# LM4F232E5QC register map
File version: 7944
Registers are 32-bit, read-write, no defined reset value unless marked. A register's access mark holds for its fields unless they carry their own. Offsets are from the block's base; [hi:lo] are bit positions; {n}, {i} and the like mark numbered series.

## EEPROM — Register map for EEPROM peripheral
Base 0x400AF000; register names take the prefix EEPROM
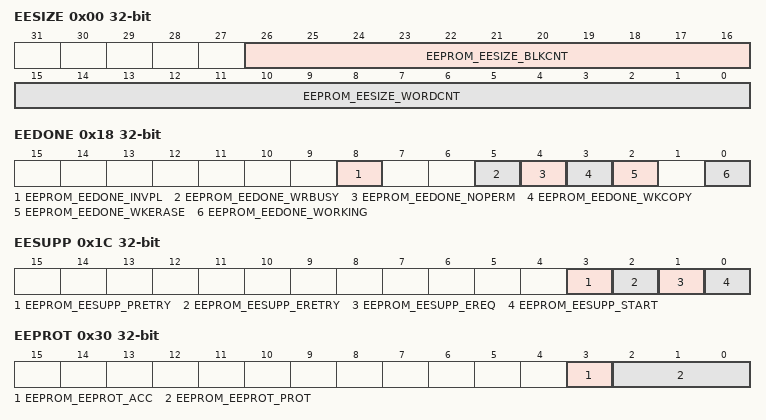
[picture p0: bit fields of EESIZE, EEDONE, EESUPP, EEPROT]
0x00 EESIZE — EEPROM Size Information
  [26:16] EEPROM_EESIZE_BLKCNT — Number of 16-Word Blocks
  [15:0] EEPROM_EESIZE_WORDCNT — Number of 32-Bit Words
0x04 EEBLOCK — EEPROM Current Block
  [15:0] EEPROM_EEBLOCK_BLOCK — Current Block
0x08 EEOFFSET — EEPROM Current Offset
  [3:0] EEPROM_EEOFFSET_OFFSET — Current Address Offset
0x10 EERDWR — EEPROM Read-Write
  [31:0] EEPROM_EERDWR_VALUE — EEPROM Read or Write Data
0x14 EERDWRINC — EEPROM Read-Write with Increment
  [31:0] EEPROM_EERDWRINC_VALUE — EEPROM Read or Write Data with Increment
0x18 EEDONE — EEPROM Done Status
  [8] EEPROM_EEDONE_INVPL — Invalid Program Voltage Level
  [5] EEPROM_EEDONE_WRBUSY — Write Busy
  [4] EEPROM_EEDONE_NOPERM — Write Without Permission
  [3] EEPROM_EEDONE_WKCOPY — Working on a Copy
  [2] EEPROM_EEDONE_WKERASE — Working on an Erase
  [0] EEPROM_EEDONE_WORKING — EEPROM Working
0x1C EESUPP — EEPROM Support Control and Status
  [3] EEPROM_EESUPP_PRETRY — Programming Must Be Retried
  [2] EEPROM_EESUPP_ERETRY — Erase Must Be Retried
  [1] EEPROM_EESUPP_EREQ — Erase Required
  [0] EEPROM_EESUPP_START — Start Erase
0x20 EEUNLOCK — EEPROM Unlock
  [31:0] EEPROM_EEUNLOCK_UNLOCK
0x30 EEPROT — EEPROM Protection
  [3] EEPROM_EEPROT_ACC — Access Control
  [2:0] EEPROM_EEPROT_PROT — Protection Control
    0=EEPROM_EEPROT_PROT_RWNPW (This setting is the default. If there is no password, the block is not protected and is readable and writable); 1=EEPROM_EEPROT_PROT_RWPW (If there is a password, the block is readable or writable only when unlocked); 2=EEPROM_EEPROT_PROT_RONPW (If there is no password, the block is readable, not writable)
{0x34+4i} EEPASS{i} (i=0..2) — EEPROM Password
  [31:0] EEPROM_EEPASS{i}_PASS — Password
0x40 EEINT — EEPROM Interrupt
  [0] EEPROM_EEINT_INT — Interrupt Enable
0x50 EEHIDE — EEPROM Block Hide
  [31:1] EEPROM_EEHIDE_HN — Hide Block
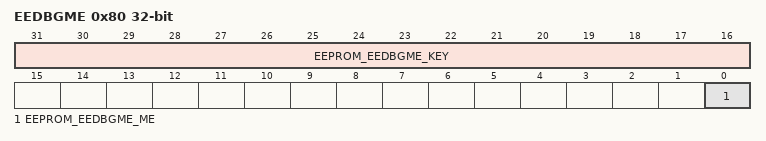
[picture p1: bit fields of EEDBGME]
0x80 EEDBGME — EEPROM Debug Mass Erase
  [31:16] EEPROM_EEDBGME_KEY — Erase Key
  [0] EEPROM_EEDBGME_ME — Mass Erase
0xFC0 EEPROMPP — EEPROM
  [4:0] EEPROM_EEPROMPP_SIZE — EEPROM Size

## SYSEXC — Register map for SYSEXC peripheral
Base 0x400F9000; register names take the prefix SYSEXC
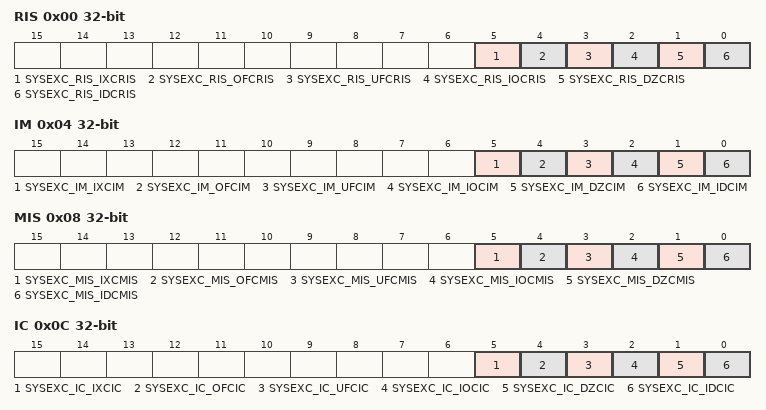
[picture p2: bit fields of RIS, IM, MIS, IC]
0x00 RIS — System Exception Raw Interrupt Status
  [5] SYSEXC_RIS_IXCRIS — Inexact Exception Flag
  [4] SYSEXC_RIS_OFCRIS — Overflow Exception Flag
  [3] SYSEXC_RIS_UFCRIS — Underflow Exception Flag
  [2] SYSEXC_RIS_IOCRIS — Invalid Operation Flag
  [1] SYSEXC_RIS_DZCRIS — Divide By 0 Exception Flag
  [0] SYSEXC_RIS_IDCRIS — Input Denormal Exception Flag
0x04 IM — System Exception Interrupt Mask
  [5] SYSEXC_IM_IXCIM — Inexact Exception Flag
  [4] SYSEXC_IM_OFCIM — Overflow Exception Flag
  [3] SYSEXC_IM_UFCIM — Underflow Exception Flag
  [2] SYSEXC_IM_IOCIM — Invalid Operation Flag
  [1] SYSEXC_IM_DZCIM — Divide By 0 Exception Flag
  [0] SYSEXC_IM_IDCIM — Input Denormal Exception Flag
0x08 MIS — System Exception Raw Interrupt Status
  [5] SYSEXC_MIS_IXCMIS — Inexact Exception Flag
  [4] SYSEXC_MIS_OFCMIS — Overflow Exception Flag
  [3] SYSEXC_MIS_UFCMIS — Underflow Exception Flag
  [2] SYSEXC_MIS_IOCMIS — Invalid Operation Flag
  [1] SYSEXC_MIS_DZCMIS — Divide By 0 Exception Flag
  [0] SYSEXC_MIS_IDCMIS — Input Denormal Exception Flag
0x0C IC wo — System Exception Interrupt Clear
  [5] SYSEXC_IC_IXCIC — Inexact Exception Flag
  [4] SYSEXC_IC_OFCIC — Overflow Exception Flag
  [3] SYSEXC_IC_UFCIC — Underflow Exception Flag
  [2] SYSEXC_IC_IOCIC — Invalid Operation Flag
  [1] SYSEXC_IC_DZCIC — Divide By 0 Exception Flag
  [0] SYSEXC_IC_IDCIC — Input Denormal Exception Flag

## HIB — Register map for HIB peripheral
Base 0x400FC000; register names take the prefix HIB
0x00 RTCC — Hibernation RTC Counter
  [31:0] HIB_RTCC — RTC Counter
0x04 RTCM0 — Hibernation RTC Match 0
  [31:0] HIB_RTCM0 — RTC Match 0
0x0C RTCLD — Hibernation RTC Load
  [31:0] HIB_RTCLD — RTC Load
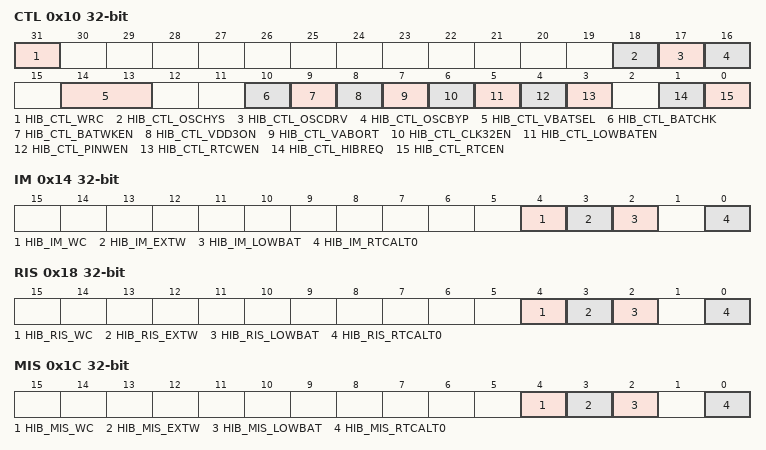
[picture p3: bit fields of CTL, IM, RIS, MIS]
0x10 CTL — Hibernation Control
  [31] HIB_CTL_WRC — Write Complete/Capable
  [18] HIB_CTL_OSCHYS — 32
  [17] HIB_CTL_OSCDRV — Oscillator Drive Capability
  [16] HIB_CTL_OSCBYP — Oscillator Bypass
  [14:13] HIB_CTL_VBATSEL — Select for Low-Battery Comparator
    0=HIB_CTL_VBATSEL_1_9V (1.9 Volts); 1=HIB_CTL_VBATSEL_2_1V (2.1 Volts (default)); 2=HIB_CTL_VBATSEL_2_3V (2.3 Volts); 3=HIB_CTL_VBATSEL_2_5V (2.5 Volts)
  [10] HIB_CTL_BATCHK — Check Battery Status
  [9] HIB_CTL_BATWKEN — Wake on Low Battery
  [8] HIB_CTL_VDD3ON — VDD Powered
  [7] HIB_CTL_VABORT — Power Cut Abort Enable
  [6] HIB_CTL_CLK32EN — Clocking Enable
  [5] HIB_CTL_LOWBATEN — Low Battery Monitoring Enable
  [4] HIB_CTL_PINWEN — External WAKE Pin Enable
  [3] HIB_CTL_RTCWEN — RTC Wake-up Enable
  [1] HIB_CTL_HIBREQ — Hibernation Request
  [0] HIB_CTL_RTCEN — RTC Timer Enable
0x14 IM — Hibernation Interrupt Mask
  [4] HIB_IM_WC — External Write Complete/Capable Interrupt Mask
  [3] HIB_IM_EXTW — External Wake-Up Interrupt Mask
  [2] HIB_IM_LOWBAT — Low Battery Voltage Interrupt Mask
  [0] HIB_IM_RTCALT0 — RTC Alert 0 Interrupt Mask
0x18 RIS — Hibernation Raw Interrupt Status
  [4] HIB_RIS_WC — Write Complete/Capable Raw Interrupt Status
  [3] HIB_RIS_EXTW — External Wake-Up Raw Interrupt Status
  [2] HIB_RIS_LOWBAT — Low Battery Voltage Raw Interrupt Status
  [0] HIB_RIS_RTCALT0 — RTC Alert 0 Raw Interrupt Status
0x1C MIS — Hibernation Masked Interrupt Status
  [4] HIB_MIS_WC — Write Complete/Capable Masked Interrupt Status
  [3] HIB_MIS_EXTW — External Wake-Up Masked Interrupt Status
  [2] HIB_MIS_LOWBAT — Low Battery Voltage Masked Interrupt Status
  [0] HIB_MIS_RTCALT0 — RTC Alert 0 Masked Interrupt Status
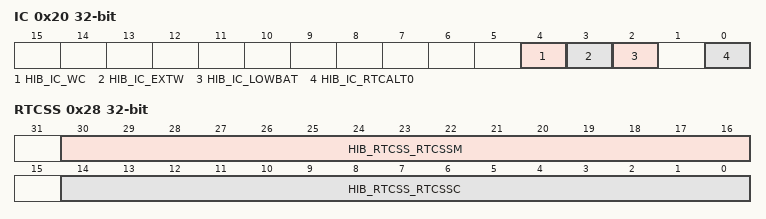
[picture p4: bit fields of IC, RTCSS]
0x20 IC — Hibernation Interrupt Clear
  [4] HIB_IC_WC — Write Complete/Capable Masked Interrupt Clear
  [3] HIB_IC_EXTW — External Wake-Up Masked Interrupt Clear
  [2] HIB_IC_LOWBAT — Low Battery Voltage Masked Interrupt Clear
  [0] HIB_IC_RTCALT0 — RTC Alert0 Masked Interrupt Clear
0x24 RTCT — Hibernation RTC Trim
  [15:0] HIB_RTCT_TRIM — RTC Trim Value
0x28 RTCSS — Hibernation RTC Sub Seconds
  [30:16] HIB_RTCSS_RTCSSM — RTC Sub Seconds Match
  [14:0] HIB_RTCSS_RTCSSC — RTC Sub Seconds Count
0x30 DATA — Hibernation Data
  [31:0] HIB_DATA_RTD — Hibernation Module NV Data

## UDMA — Register map for UDMA peripheral
Base 0x400FF000; register names take the prefix UDMA
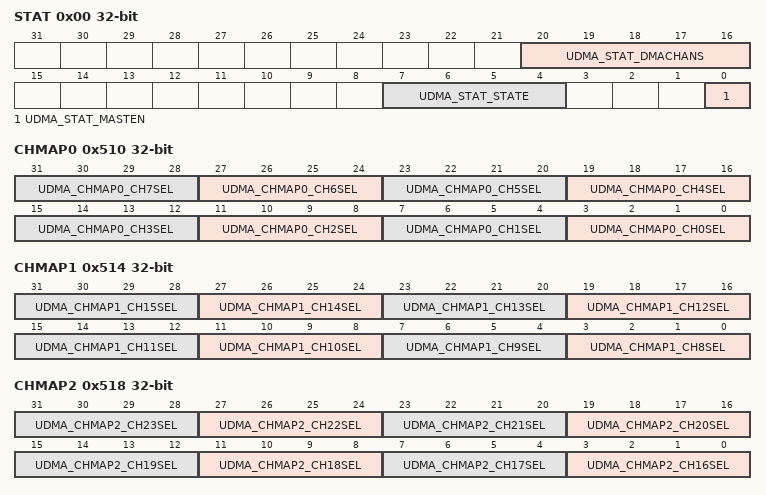
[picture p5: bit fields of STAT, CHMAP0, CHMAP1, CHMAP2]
0x00 STAT — DMA Status
  [20:16] UDMA_STAT_DMACHANS — Available uDMA Channels Minus 1
  [7:4] UDMA_STAT_STATE — Control State Machine Status
    0=UDMA_STAT_STATE_IDLE (Idle); 1=UDMA_STAT_STATE_RD_CTRL (Reading channel controller data); 2=UDMA_STAT_STATE_RD_SRCENDP (Reading source end pointer); 3=UDMA_STAT_STATE_RD_DSTENDP (Reading destination end pointer); 4=UDMA_STAT_STATE_RD_SRCDAT (Reading source data); 5=UDMA_STAT_STATE_WR_DSTDAT (Writing destination data); 6=UDMA_STAT_STATE_WAIT (Waiting for uDMA request to clear); 7=UDMA_STAT_STATE_WR_CTRL (Writing channel controller data); 8=UDMA_STAT_STATE_STALL (Stalled); 9=UDMA_STAT_STATE_DONE (Done); 10=UDMA_STAT_STATE_UNDEF (Undefined)
  [0] UDMA_STAT_MASTEN — Master Enable Status
0x04 CFG wo — DMA Configuration
  [0] UDMA_CFG_MASTEN — Controller Master Enable
0x08 CTLBASE — DMA Channel Control Base Pointer
  [31:10] UDMA_CTLBASE_ADDR — Channel Control Base Address
0x0C ALTBASE — DMA Alternate Channel Control Base Pointer
  [31:0] UDMA_ALTBASE_ADDR — Alternate Channel Address Pointer
0x10 WAITSTAT — DMA Channel Wait-on-Request Status
  [31:0] UDMA_WAITSTAT_WAITREQ — Channel [n] Wait Status
0x14 SWREQ wo — DMA Channel Software Request
  [31:0] UDMA_SWREQ — Channel [n] Software Request
0x18 USEBURSTSET — DMA Channel Useburst Set
  [31:0] UDMA_USEBURSTSET_SET — Channel [n] Useburst Set
0x1C USEBURSTCLR wo — DMA Channel Useburst Clear
  [31:0] UDMA_USEBURSTCLR_CLR — Channel [n] Useburst Clear
0x20 REQMASKSET — DMA Channel Request Mask Set
  [31:0] UDMA_REQMASKSET_SET — Channel [n] Request Mask Set
0x24 REQMASKCLR wo — DMA Channel Request Mask Clear
  [31:0] UDMA_REQMASKCLR_CLR — Channel [n] Request Mask Clear
0x28 ENASET — DMA Channel Enable Set
  [31:0] UDMA_ENASET_SET — Channel [n] Enable Set
0x2C ENACLR wo — DMA Channel Enable Clear
  [31:0] UDMA_ENACLR_CLR — Clear Channel [n] Enable Clear
0x30 ALTSET — DMA Channel Primary Alternate Set
  [31:0] UDMA_ALTSET_SET — Channel [n] Alternate Set
0x34 ALTCLR wo — DMA Channel Primary Alternate Clear
  [31:0] UDMA_ALTCLR_CLR — Channel [n] Alternate Clear
0x38 PRIOSET — DMA Channel Priority Set
  [31:0] UDMA_PRIOSET_SET — Channel [n] Priority Set
0x3C PRIOCLR wo — DMA Channel Priority Clear
  [31:0] UDMA_PRIOCLR_CLR — Channel [n] Priority Clear
0x4C ERRCLR — DMA Bus Error Clear
  [0] UDMA_ERRCLR_ERRCLR — uDMA Bus Error Status
0x500 CHASGN — DMA Channel Assignment
  [31:0] UDMA_CHASGN — Channel [n] Assignment Select
    0=UDMA_CHASGN_PRIMARY (Use the primary channel assignment); 1=UDMA_CHASGN_SECONDARY (Use the secondary channel assignment)
0x504 CHIS — DMA Channel Interrupt Status
  [31:0] UDMA_CHIS — Channel [n] Interrupt Status
0x510 CHMAP0 — DMA Channel Map Select 0
  [4n+3:4n] UDMA_CHMAP0_CH{n}SEL (n=0..7) — uDMA Channel {n} Source Select
0x514 CHMAP1 — DMA Channel Map Select 1
  [4n-29:4n-32] UDMA_CHMAP1_CH{n}SEL (n=8..15) — uDMA Channel {n} Source Select
0x518 CHMAP2 — DMA Channel Map Select 2
  [4n-61:4n-64] UDMA_CHMAP2_CH{n}SEL (n=16..23) — uDMA Channel {n} Source Select
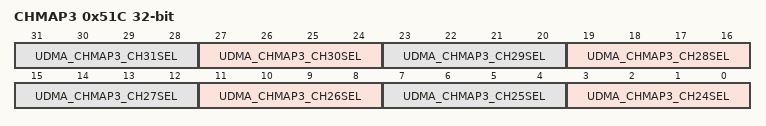
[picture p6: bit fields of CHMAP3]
0x51C CHMAP3 — DMA Channel Map Select 3
  [4n-93:4n-96] UDMA_CHMAP3_CH{n}SEL (n=24..31) — uDMA Channel {n} Source Select
